# f28004x_erad_global_regs register map
Vendor: Texas Instruments
Peripheral module from a debugger description file (folder C2000).
Address unit: 16 bits
Registers are 16-bit, read-write, no defined reset value unless marked. A register's access mark holds for its fields unless they carry their own. Offsets are as the file gives them; lines under a group give offsets from that group; [hi:lo] are bit positions; {n}, {i} and the like mark numbered series; 'fields as' and 'values as' point back to an identical list; <NAME> marks a mode.

## ERAD_GLOBAL_REGS — ERAD GLOBAL Registers
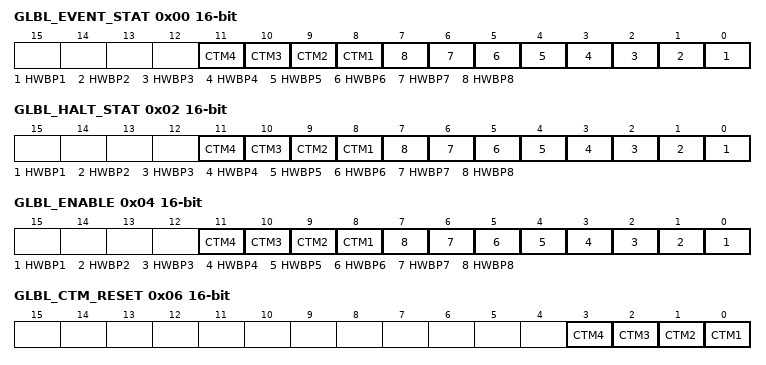
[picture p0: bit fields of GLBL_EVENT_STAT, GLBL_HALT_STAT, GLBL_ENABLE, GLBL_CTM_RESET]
0x00 GLBL_EVENT_STAT ro — Global Event Status Register
  [n+7] CTM{n} (n=1..4) — Counter Module Event Status
  [n-1] HWBP{n} (n=1..8) — Bus Comparator Module Event Status
0x02 GLBL_HALT_STAT ro — Global Halt Status Register
  [n+7] CTM{n} (n=1..4) — Counter Module Halt Status
  [n-1] HWBP{n} (n=1..8) — Bus Comparator Module Halt Status
0x04 GLBL_ENABLE — Global Enable Register
  [n+7] CTM{n} (n=1..4) — Counter Module Global Enable
  [n-1] HWBP{n} (n=1..8) — Bus Comparator Module Global Enable
0x06 GLBL_CTM_RESET — Global Counter Reset
  [n-1] CTM{n} (n=1..4) — Global Reset for the counters
0x0A GLBL_OWNER — Global Ownership
  [1:0] OWNER — Global Ownership Bits
